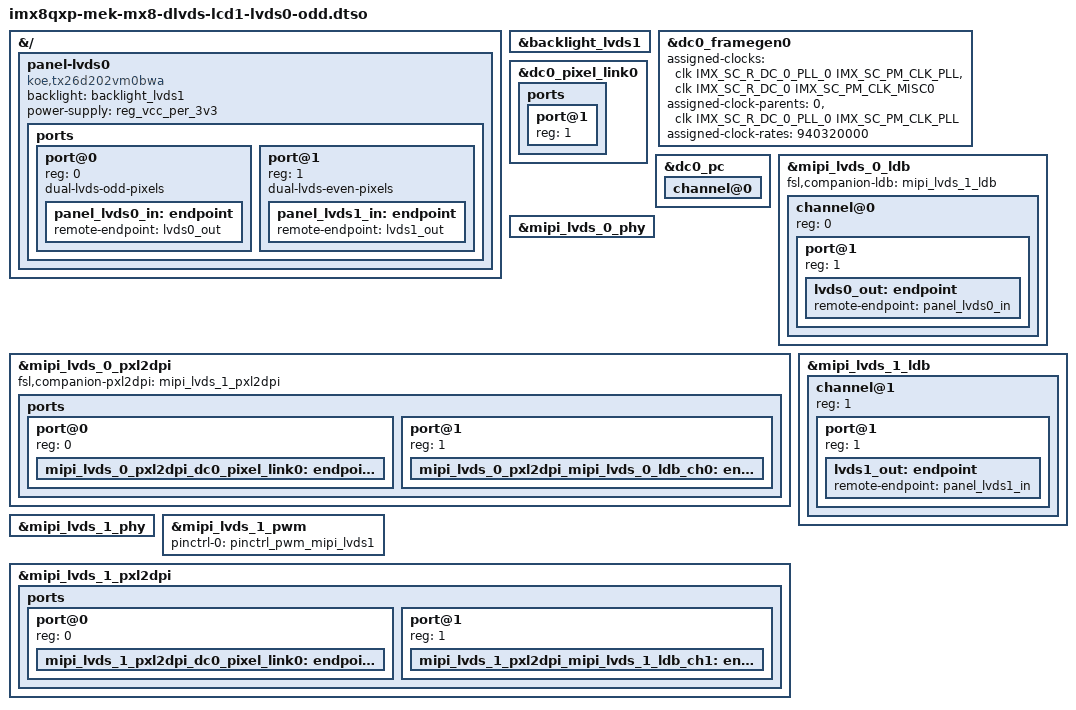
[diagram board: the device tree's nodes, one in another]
// SPDX-License-Identifier: (GPL-2.0+ OR MIT)
/*
 * Copyright 2024 NXP
 */

/dts-v1/;
/plugin/;

#include <dt-bindings/firmware/imx/rsrc.h>

&{/} {
	panel-lvds0 {
		compatible = "koe,tx26d202vm0bwa";
		backlight = <&backlight_lvds1>;
		power-supply = <&reg_vcc_per_3v3>;

		ports {
			#address-cells = <1>;
			#size-cells = <0>;

			port@0 {
				reg = <0>;
				dual-lvds-odd-pixels;

				panel_lvds0_in: endpoint {
					remote-endpoint = <&lvds0_out>;
				};
			};

			port@1 {
				reg = <1>;
				dual-lvds-even-pixels;

				panel_lvds1_in: endpoint {
					remote-endpoint = <&lvds1_out>;
				};
			};
		};
	};
};

&backlight_lvds1 {
	status = "okay";
};

&dc0_framegen0 {
	assigned-clocks = <&clk IMX_SC_R_DC_0_PLL_0 IMX_SC_PM_CLK_PLL>,
			  <&clk IMX_SC_R_DC_0 IMX_SC_PM_CLK_MISC0>;
	assigned-clock-parents = <0>,
				 <&clk IMX_SC_R_DC_0_PLL_0 IMX_SC_PM_CLK_PLL>;
	assigned-clock-rates = <940320000>;
};

&dc0_pixel_link0 {
	status = "okay";

	ports {
		#address-cells = <1>;
		#size-cells = <0>;

		port@1 {
			reg = <1>;

			status = "okay";
		};
	};
};

&dc0_pc {
	status = "okay";

	channel@0 {
		status = "okay";
	};
};

&mipi_lvds_0_ldb {
	#address-cells = <1>;
	#size-cells = <0>;
	fsl,companion-ldb = <&mipi_lvds_1_ldb>;
	status = "okay";

	channel@0 {
		#address-cells = <1>;
		#size-cells = <0>;
		reg = <0>;
		status = "okay";

		port@1 {
			reg = <1>;

			lvds0_out: endpoint {
				remote-endpoint = <&panel_lvds0_in>;
			};
		};
	};
};

&mipi_lvds_0_phy {
	status = "okay";
};

&mipi_lvds_0_pxl2dpi {
	fsl,companion-pxl2dpi = <&mipi_lvds_1_pxl2dpi>;
	status = "okay";

	ports {
		#address-cells = <1>;
		#size-cells = <0>;

		port@0 {
			reg = <0>;

			mipi_lvds_0_pxl2dpi_dc0_pixel_link0: endpoint@0 {
				status = "okay";
			};
		};

		port@1 {
			reg = <1>;

			mipi_lvds_0_pxl2dpi_mipi_lvds_0_ldb_ch0: endpoint@0 {
				status = "okay";
			};
		};
	};
};

&mipi_lvds_1_ldb {
	#address-cells = <1>;
	#size-cells = <0>;
	status = "okay";

	channel@1 {
		#address-cells = <1>;
		#size-cells = <0>;
		reg = <1>;
		status = "okay";

		port@1 {
			reg = <1>;

			lvds1_out: endpoint {
				remote-endpoint = <&panel_lvds1_in>;
			};
		};
	};
};

&mipi_lvds_1_phy {
	status = "okay";
};

&mipi_lvds_1_pwm {
	pinctrl-names = "default";
	pinctrl-0 = <&pinctrl_pwm_mipi_lvds1>;
	status = "okay";
};

&mipi_lvds_1_pxl2dpi {
	status = "okay";

	ports {
		#address-cells = <1>;
		#size-cells = <0>;

		port@0 {
			reg = <0>;

			mipi_lvds_1_pxl2dpi_dc0_pixel_link0: endpoint@1 {
				status = "okay";
			};
		};

		port@1 {
			reg = <1>;

			mipi_lvds_1_pxl2dpi_mipi_lvds_1_ldb_ch1: endpoint@1 {
				status = "okay";
			};
		};
	};
};
